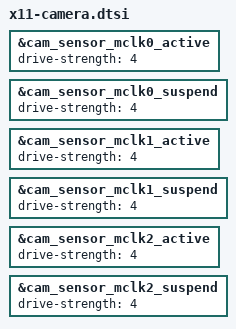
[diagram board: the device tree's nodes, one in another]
/* Copyright (c) 2017, The Linux Foundation. All rights reserved.
 *
 * This program is free software; you can redistribute it and/or modify
 * it under the terms of the GNU General Public License version 2 and
 * only version 2 as published by the Free Software Foundation.
 *
 * This program is distributed in the hope that it will be useful,
 * but WITHOUT ANY WARRANTY; without even the implied warranty of
 * MERCHANTABILITY or FITNESS FOR A PARTICULAR PURPOSE.  See the
 * GNU General Public License for more details.
 */

&cam_sensor_mclk0_active {
    drive-strength = <4>; /* 4 MA */
};

&cam_sensor_mclk0_suspend {
    drive-strength = <4>; /* 4 MA */
};

&cam_sensor_mclk1_active {
    drive-strength = <4>; /* 4 MA */
};

&cam_sensor_mclk1_suspend {
    drive-strength = <4>; /* 4 MA */  
};

&cam_sensor_mclk2_active {
    drive-strength = <4>; /* 4 MA */
};

&cam_sensor_mclk2_suspend {
    drive-strength = <4>; /* 4 MA */
};
